# NPCX498S register map
File version: 1.0
Registers are 8-bit, read-write, reset 0x0 unless marked. A register's access mark holds for its fields unless they carry their own. Offsets are from the block's base; [hi:lo] are bit positions; {n}, {i} and the like mark numbered series; 'fields as' and 'values as' point back to an identical list.

## PWM0
Base 0x40080000
Same registers: PWM1 0x40082000, PWM2 0x40084000, PWM3 0x40086000, PWM4 0x40088000, PWM5 0x4008A000, PWM6 0x4008C000, PWM7 0x4008E000
0x00 PRSCn 16-bit (reset mask 0xFF) — Clock Prescaler Register (PRSCn)
0x02 CTR_RSn 16-bit (reset mask 0xFF) — Cycle Time for Rise Duty Cycle Register (CTR_RSn)
  [11:0] CTR_RS11_0 — Cycle Time Value for Rise Duty Cycle
0x02 CTRn 16-bit (reset mask 0xFF) — Cycle Time Register (CTRn)
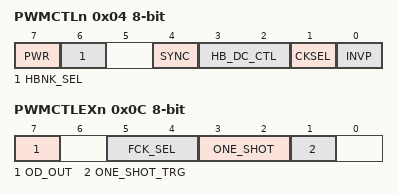
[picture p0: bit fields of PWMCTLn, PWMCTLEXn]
0x04 PWMCTLn — PWM Control Register (PWMCTLn)
  [7] PWR — Power Mode
  [6] HBNK_SEL — Heartbeat Bank Select
  [4] SYNC — Operation Synchronization
  [3:2] HB_DC_CTL — Heartbeat Duty Cycle Control
  [1] CKSEL — Input Clock Select
  [0] INVP — Inverse PWM Output
0x05 N_STEP_RSn — Number of Steps for Rise Duty Cycle Register (N_STEP_RSn)
0x06 MAX_DC_RSn 16-bit (reset mask 0xFF) — Maximum Duty Cycle Rise Register (MAX_DC_RSn)
  [11:0] MAX_DC_RS11_0 — Maximum Duty Cycle Rise Value
0x06 DCRn 16-bit (reset mask 0xFF) — Duty Cycle Register (DCRn)
0x08 CTR_FLn 16-bit (reset mask 0xFF) — Cycle Time for Fall Duty Cycle Register (CTR_FLn)
  [11:0] CTR_FL11_0 — Cycle Time Value for Fall Duty Cycle
0x0A MAX_DC_FLn 16-bit (reset mask 0xFF) — Maximum Duty Cycle Fall Register (MAX_DC_FLn)
  [11:0] MAX_DC_FL11_0 — Maximum Duty Cycle Fall Value
0x0C PWMCTLEXn — PWM Control Extended Register (PWMCTLEXn)
  [7] OD_OUT — Open-Drain Output
  [5:4] FCK_SEL — Fixed Frequency Clock Select
  [3:2] ONE_SHOT — One-Shot Mode
  [1] ONE_SHOT_TRG — One-Shot Trigger
0x0D N_STEP_FLn — Number of Steps for Fall Duty Cycle Register (N_STEP_FLn)
0x0E EXT_ONn — Extend ON Time Register (EXT_ONn)
0x0F EXT_OFFn — Extend OFF Time Register (EXT_OFFn)
0x10 MIN_DC_RSFLn 16-bit (reset mask 0xFF) — Minimum Duty Cycle Rise/Fall Register (MIN_DC_RSFLn)
  [11:0] MIN_DC_RSFL11_0 — Minimum Duty Cycle Rise/Fall Value

## ESHM
Base 0x40010080
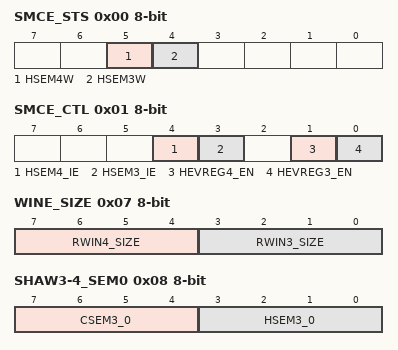
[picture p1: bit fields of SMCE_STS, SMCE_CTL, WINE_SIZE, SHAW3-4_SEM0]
0x00 SMCE_STS — Extended Shared Memory Core Status Register (SMCE_STS)
  [5] HSEM4W — Host Semaphore 4 Written
  [4] HSEM3W — Host Semaphore 3 Written
0x01 SMCE_CTL — Extended Shared Memory Core Control Register (SMCE_CTL)
  [4] HSEM4_IE — Enable Interrupt by Host Semaphore 4 Written
  [3] HSEM3_IE — Enable Interrupt by Host Semaphore 3 Written
  [1] HEVREG4_EN — Host Event Registers Window 4 Enable
  [0] HEVREG3_EN — Host Event Registers Window 3 Enable
0x07 WINE_SIZE — Extended Shared Access Windows Size Register (WINE_SIZE)
  [7:4] RWIN4_SIZE — RAM Access Window 4, Size Select
  [3:0] RWIN3_SIZE — RAM Access Window 3, Size Select
0x08 SHAW3-4_SEM0 — Shared Access Window 3-4, Semaphore Register (SHAW3-4_SEM)
  [7:4] CSEM3_0 — Core Semaphore Bits 3-0
  [3:0] HSEM3_0 — Host Semaphore Bits 3-0
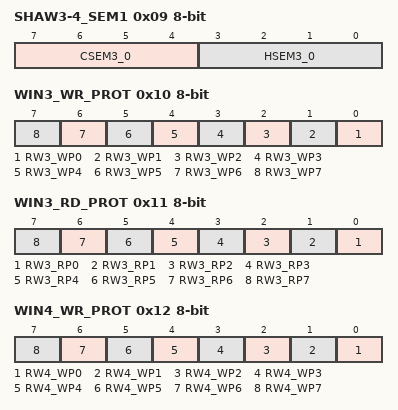
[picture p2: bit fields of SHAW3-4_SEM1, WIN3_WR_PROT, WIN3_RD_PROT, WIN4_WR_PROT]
0x09 SHAW3-4_SEM1 — Shared Access Window 3-4, Semaphore Register (SHAW3-4_SEM)
  fields as SHAW3-4_SEM0
0x10 WIN3_WR_PROT — Shared Access Window 3 Write Protect Register (WIN3_WR_PROT)
  [n] RW3_WP{n} (n=0..7) — RAM Access Window 3 Write Protect {n}
0x11 WIN3_RD_PROT — Shared Access Window 3 Read Protect Register (WIN3_RD_PROT)
  [n] RW3_RP{n} (n=0..7) — RAM Access Window 3 Read Protect {n}
0x12 WIN4_WR_PROT — Shared Access Window 4 Write Protect Register (WIN4_WR_PROT)
  [n] RW4_WP{n} (n=0..7) — RAM Access Window 4 Write Protect {n}
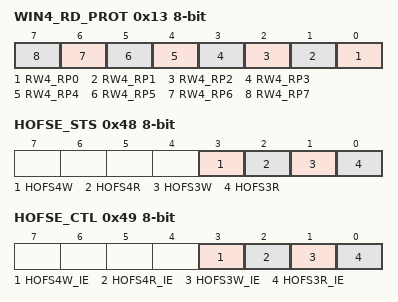
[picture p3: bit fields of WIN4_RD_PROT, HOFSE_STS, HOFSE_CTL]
0x13 WIN4_RD_PROT — Shared Access Window 4 Read Protect Register (WIN4_RD_PROT)
  [n] RW4_RP{n} (n=0..7) — RAM Access Window 4 Read Protect {n}
0x20 WIN_BASE3 32-bit (reset mask 0xFF) — Shared Access Window 3 Base Register (WIN_BASE3)
0x24 WIN_BASE4 32-bit (reset mask 0xFF) — Shared Access Window 4 Base Register (WIN_BASE4)
0x48 HOFSE_STS — Host_Offset in Windows 3,4 Status Register (HOFSE_STS)
  [3] HOFS4W — Host Write to Offset in Window 4 Status
  [2] HOFS4R — Host Read from Offset in Window 4 Status
  [1] HOFS3W — Host Write to Offset in Window 3 Status
  [0] HOFS3R — Host Read from Offset in Window 3 Status
0x49 HOFSE_CTL — Host_Offset in Windows 3,4 Control Register (HOFSE_CTL)
  [3] HOFS4W_IE — Enable Interrupt by Host Write to Offset in Window 4
  [2] HOFS4R_IE — Enable Interrupt by Host Read to Offset in Window 4
  [1] HOFS3W_IE — Enable Interrupt by Host Write to Offset in Window 3
  [0] HOFS3R_IE — Enable Interrupt by Host Read to Offset in Window 3
0x4A COFS4 16-bit (reset mask 0xFF) — Core_Offset in Window 4 Address (COFS4)
  [11:0] COFS4_DAT — Core_Offset in Window 4, Data
0x4C COFS3 16-bit (reset mask 0xFF) — Core_Offset in Window 3 Address (COFS3)
  [11:0] COFS3_DAT — Core Offset in Window 3, Data

## SPIP
Base 0x400D2000
0x00 SPIP_DATA 16-bit (reset mask 0xFF) — SPIP Data In Out Register
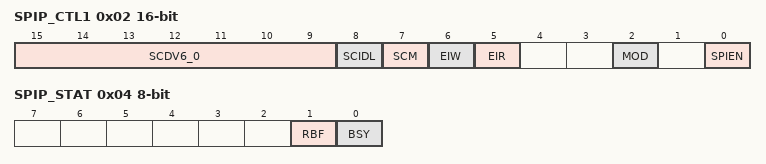
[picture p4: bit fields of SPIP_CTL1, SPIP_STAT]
0x02 SPIP_CTL1 16-bit (reset mask 0xFF) — SPIP Control 1 Register (SPIP_CTL1)
  [15:9] SCDV6_0 — Shift Clock Divider Value
  [8] SCIDL — Value of SPI_SCLK when Bus is Idle
  [7] SCM — Clocking Mode
  [6] EIW — Enable Interrupt for Write
  [5] EIR — Enable Interrupt for Read
  [2] MOD — Data Interface Mode
  [0] SPIEN — SPI Enable
0x04 SPIP_STAT — SPIP Status Register (SPIP_STAT)
  [1] RBF — Read Buffer Full
  [0] BSY — Shift Register Busy

## SYS_GLUE
Base 0x400A5000
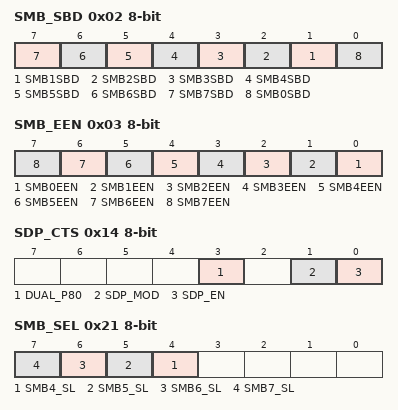
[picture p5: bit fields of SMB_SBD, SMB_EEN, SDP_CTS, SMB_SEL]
0x02 SMB_SBD — SMBus/I2C Start Bit Detection Register (SMB_SBD)
  [n] SMB{n}SBD (n=1..7) — SMBus/I2C Module {n} Start Bit Detection
  [0] SMB0SBD — SMBus/I2C 0 Start Bit Detection
0x03 SMB_EEN — SMBus/I2C Event Enable Register (SMB_EEN)
  [n] SMB{n}EEN (n=0..7) — SMBus/I2C {n} Event Enable
0x10 SDPD0 — Simple Debug Port Data 0 Register (SDPD0)
0x12 SDPD1 — Simple Debug Port Data 1 Register (SDPD1)
0x14 SDP_CTS — Simple Debug Port Control and Status Register (SDP_CTS)
  [3] DUAL_P80 — Dual Port 80 Display
  [1] SDP_MOD — SDP Mode Select
  [0] SDP_EN — SDP Enable
0x21 SMB_SEL — SMBus/I2C Bus Select Register (SMB_SEL)
  [n] SMB{n}_SL (n=4..7) — SMBus/I2C {n} Interface-Select
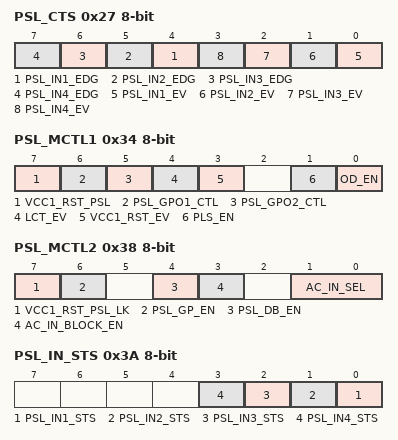
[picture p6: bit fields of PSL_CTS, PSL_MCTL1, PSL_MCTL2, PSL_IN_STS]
0x27 PSL_CTS — PSL Control and Status Register (PSL_CTS)
  [n+3] PSL_IN{n}_EDG (n=1..4) — PSL_IN{n} Edge Mode
  [n-1] PSL_IN{n}_EV (n=1..4) — PSL_IN{n} Event
0x34 PSL_MCTL1 — PSL Miscellaneous Control 1 Register (PSL_MCTL1)
  [7] VCC1_RST_PSL — VCC1_RST Enable to PSL
  [6] PSL_GPO1_CTL — PSL_GPO1 Control
  [5] PSL_GPO2_CTL — PSL_GPO2 Control
  [4] LCT_EV — LCT Event
  [3] VCC1_RST_EV — VCC1_RST Event
  [1] PLS_EN — Pulse Mode Enable
  [0] OD_EN — Open-Drain Output Enable
0x38 PSL_MCTL2 — PSL Miscellaneous Control 2 Register (PSL_MCTL2)
  [7] VCC1_RST_PSL_LK — VCC1_RST Enable to PSL Lock
  [6] PSL_GP_EN — PSL Glitch Protection Enable
  [4] PSL_DB_EN — PSL Debouncer Enable
  [3] AC_IN_BLOCK_EN — AC_IN Blocking of LCT PSL Event, Enable
  [1:0] AC_IN_SEL — AC_IN Input Select
0x3A PSL_IN_STS — PSL Input Status Register (PSL_IN_STS)
  [n-1] PSL_IN{n}_STS (n=1..4) — PSL_IN{n} Status
0x3C PSL_DBC — PSL Debounce Register (PSL_DBC)
  [2:0] BC_SEL — PSL Debounce Select
0x40 SNT_STS — Snooze Timer Status Register (SNT_STS)
  [1:0] SNT_END — Snooze Timer Count Ended
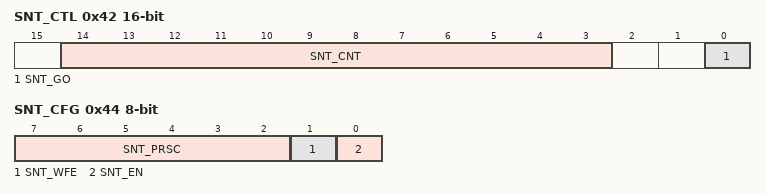
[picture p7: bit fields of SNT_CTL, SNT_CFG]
0x42 SNT_CTL 16-bit (reset mask 0xFF) — Snooze Timer Control Register (SNT_CTL)
  [14:3] SNT_CNT — Snooze Timer Count
  [0] SNT_GO — Snooze Timer Start
0x44 SNT_CFG — Snooze Timer Configuration Register (SNT_CFG)
  [7:2] SNT_PRSC — Snooze Timer Prescaler
  [1] SNT_WFE — Snooze Timer Event Enable
  [0] SNT_EN — Snooze Timer Function Enable

## TWD
Base 0x400D8000
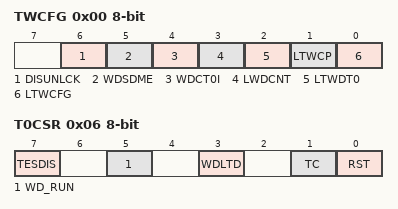
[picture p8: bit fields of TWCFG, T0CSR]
0x00 TWCFG — Timer and Watchdog Configuration Register (TWCFG)
  [6] DISUNLCK — Disable Unlock
  [5] WDSDME — Watchdog Touch Select
  [4] WDCT0I — Watchdog Clock Select
  [3] LWDCNT — Lock Watchdog Counter
  [2] LTWDT0 — Lock T0 Timer
  [1] LTWCP — Lock Prescalers
  [0] LTWCFG — Lock Watchdog Configuration
0x02 TWCP — Timer and Watchdog Clock Prescaler Register (TWCP)
  [3:0] MDIV — default
0x04 TWDT0 16-bit (reset mask 0xFF) — TWD Timer 0 Register (TWDT0)
0x06 T0CSR — TWDT0 Control and Status Register (T0CSR)
  [7] TESDIS — Too Early Service Disable
  [5] WD_RUN — Watchdog Run Status
  [3] WDLTD — Watchdog Last Touch Delay
  [1] TC — Terminal Count
  [0] RST — Reset
0x08 WDCNT — Watchdog Count Register (WDCNT)
0x0A WDSDM — Watchdog Service Data Match Register (WDSDM)
0x0C TWMT0 16-bit (reset mask 0xFF) — TWD Timer 0 Counter Register (TWMT0)
0x0E TWMWD — Watchdog Counter Register (TWMWD)
0x10 WDCP — Watchdog Clock Prescaler Register (WDCP)
  [3:0] WDIV — default
